# S32M24x register map
Vendor: NXP Semiconductors; File version: 1.5
CPU: CM4 r0p1, little endian, MPU, FPU, VTOR, 4 interrupt priority bits
Registers are 32-bit, read-write, reset 0x0 unless marked. A register's access mark holds for its fields unless they carry their own. Offsets are from the block's base; [hi:lo] are bit positions; {n}, {i} and the like mark numbered series; 'fields as' and 'values as' point back to an identical list.

## DPGA_AE — DPGA
Base 0x00000140
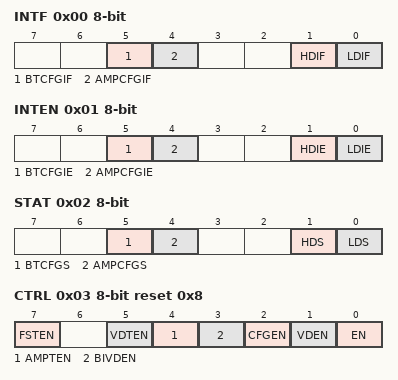
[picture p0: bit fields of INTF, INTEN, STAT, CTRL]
0x00 INTF 8-bit write-1-clears — Interrupt Flags
  [5] BTCFGIF write-1-clears — BTCFG Interrupt Flag
    0=PAR_GOOD (The parity check has been ok since the last clearing of this bit.); 1=PAR_FAIL (A failure in the parity check was detected since the last clearing of this bit.)
  [4] AMPCFGIF write-1-clears — AMPCFG Interrupt Flag
    values as BTCFGIF
  [1] HDIF write-1-clears — High detect interrupt flag
    0=HDIF_LOW (No high voltage condition has been detected since the last clearing of this bit.); 1=HDIF_HIGH (A high voltage condition has been detected since the last clearing of this bit.)
  [0] LDIF write-1-clears — Low detect interrupt flag
    0=LDIF_LOW (No low voltage condition has been detected since the last clearing of this bit.); 1=LDIF_HIGH (A low voltage condition has been detected since the last clearing of this bit.)
0x01 INTEN 8-bit — Interrupt enable
  [5] BTCFGIE — BTCFG interrupt enable
    0=DISABLED (The interrupt will not be created.); 1=ENABLED (The interrupt will be created.)
  [4] AMPCFGIE — AMPCFG interrupt enable
    values as BTCFGIE
  [1] HDIE — High detect interrupt enable
    0=HDIE_DISABLED (The high detect interrupt flag INTF[HDIF] cannot assert any interrupt.); 1=HDIE_ENABLED (The high detect interrupt flag INTF[HDIF] can assert the high detect interrupt.)
  [0] LDIE — Low detect interrupt enable
    0=LDIE_DISABLED (The low detect interrupt flag INTF[LDIF] cannot assert any interrupt.); 1=LDIE_ENABLED (The low detect interrupt flag INTF[LDIF] can assert the low detect interrupt.)
0x02 STAT 8-bit ro — Status
  [5] BTCFGS — BTCFG status
    0=EVEN (The count of bits set to 1 in the register is even.); 1=ODD (The count of bits set to 1 in the register is odd.)
  [4] AMPCFGS — AMPCFG status
    values as BTCFGS
  [1] HDS — High detect filtered status
    0=HDFILTS_LOW (No high voltage condition is detected.); 1=HDFILTS_HIGH (A high voltage condition is detected, so the amplifier output voltage has been higher than the limit configured in VDCFG[HDLIM] for longer than the filter time defined in VDCFG[HDFILT] .)
  [0] LDS — Low detect filtered status
    0=LDFILTS_LOW (No low voltage condition is detected.); 1=LDFILTS_HIGH (A low voltage condition is detected, so the amplifier output voltage has been lower than the limit configured in VDCFG[LDLIM] for longer than the filter time defined in VDCFG[LDFILT] .)
0x03 CTRL 8-bit reset 0x8 — Control
  [7] FSTEN — Functional Self-Test Enable
    0=DISABLE (The functional self-tests cannot be activated.); 1=ENABLE (The functional self-tests can be activated.)
  [5] VDTEN — Voltage Detector Test Enable
    0=VDTEN_DISABLED (The high and low detectors are in functional mode.); 1=VDTEN_ENABLED (If CTRL[FSTEN] is set, the functional self-test of the high and low detectors are active.)
  [4] AMPTEN — Amplifier test enable
    0=AMPTEN_DISABLED (The amplifier is in functional mode.); 1=AMPTEN_ENABLE (If CTRL[FSTEN] is set, the functional self-test of the amplifier is active.)
  [3] BIVDEN — Bipolar Voltage Detector Enable
    0=BIVDEN_DISABLED (disabled); 1=BIVDEN_ENABLED (enabled)
  [2] CFGEN — Configuration Mode Enable
    0=DISABLED (The DPGA is in functional mode.); 1=ENABLED (The DPGA is in configuration mode.)
  [1] VDEN — Voltage Detector Enable
    0=VDEN_DISABLED (disabled); 1=VDEN_ENABLED (enabled)
  [0] EN — Enable
    0=DISABLED (The DPGA is disabled, all features are turned off. Select this when you do not want to utilize the DPGA.); 1=ENABLED (The DPGA is enabled, all features are used as configured.)
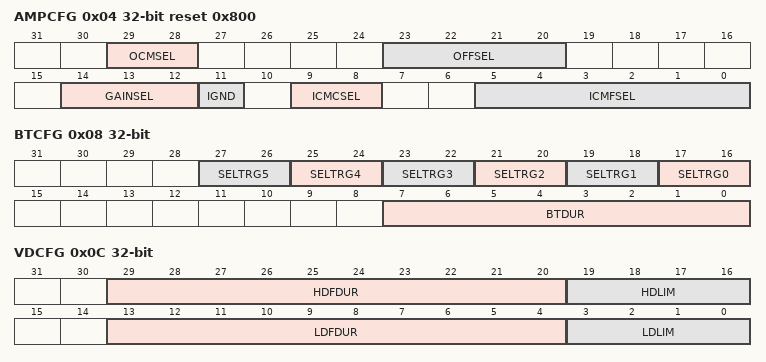
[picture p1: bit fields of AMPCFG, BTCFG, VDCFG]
0x04 AMPCFG reset 0x800 — Amplifier Configuration
  [29:28] OCMSEL — Output Common Mode Configuration
    0=reference voltage divided by 12; 1=reference voltage divided by 6; 2=reference voltage divided by 4; 3=reference voltage divided by 2
  [23:20] OFFSEL — Offset compensation configuration
    0=no offset compensation; 1=3 mV positive compensation; 2=6 mV positive compensation; 7=21 mV positive compensation; 8=no offset compensation; 9=3 mV negative compensation; 10=6 mV negative compensation; 15=21 mV negative compensation
  [14:12] GAINSEL — Gain selection
    0=amplify by 8; 1=amplify by 16; 2=amplify by 24; 3=amplify by 32; 4=amplify by 40; 5=amplify by 50; 6=amplify by 65; 7=amplify by 80
  [11] IGND — Input Grounded
    0=FUNC (Functional connection); 1=GND (Connection to ground)
  [9:8] ICMCSEL — Input Common Mode Coarse Configuration
    0=no common mode shift; 1=common mode shift with 200 uA current out of both differential inputs; 2=common mode shift with 100 uA current out of both differential inputs; 3=common mode shift with 50 uA current out of both differential inputs
  [5:0] ICMFSEL — Input Common Mode Fine Configuration
    0=ICMCSEL*1.000 out of minus input; 1=ICMCSEL*1.0025 out of minus input; 2=ICMCSEL*1.005 out of minus input; 31=ICMCSEL*1.0775 out of minus input; 32=ICMCSEL*1.000 out of plus input; 33=ICMCSEL*1.0025 out of plus input; 34=ICMCSEL*1.005 out of plus input; 63=ICMCSEL*1.0775 out of plus input
0x08 BTCFG — Blanking time configuration
  [2n+17:2n+16] SELTRG{n} (n=0..5) — Select Trigger {n}
    0=ZERO (The trigger n cannot start the blanking time counter); 1=ONE (The falling edge of the trigger n starts the counting from 0.); 2=TWO (The rising edge of the trigger n starts the counting from 0.); 3=THREE (Any edge of the trigger n starts the counting from 0.)
  [7:0] BTDUR — Blanking time duration
0x0C VDCFG — Voltage Detector Configuration
  [29:20] HDFDUR — High Detect Filter Duration
  [19:16] HDLIM — High Detect Limit
  [13:4] LDFDUR — Low Detect Filter Duration
  [3:0] LDLIM — Low Detect Limit
